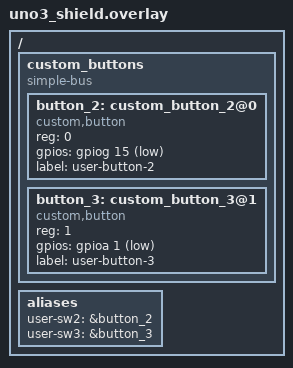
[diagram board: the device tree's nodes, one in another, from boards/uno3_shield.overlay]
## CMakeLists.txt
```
# SPDX-License-Identifier: Apache-2.0

cmake_minimum_required(VERSION 3.20.0)

set(ZEPHYR_EXTRA_MODULES
    "${CMAKE_SOURCE_DIR}/../modules/button"
    "${CMAKE_SOURCE_DIR}/../modules/say_hello"
)

find_package(Zephyr REQUIRED HINTS $ENV{ZEPHYR_BASE})
project(custom-button)

target_sources(app PRIVATE src/main.c)
```

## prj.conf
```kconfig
CONFIG_GPIO=y

# for random generator
CONFIG_STACK_POINTER_RANDOM=0
CONFIG_TEST_RANDOM_GENERATOR=y
CONFIG_TIMER_RANDOM_GENERATOR=y
CONFIG_TEST_CSPRNG_GENERATOR=y

# for float number print
# -LIBC_ERRNO y
# -PICOLIBC_IO_FLOAT n
# -PICOLIBC_IO_LONG_LONG y
# -PICOLIBC_USE_MODULE n
# -PICOLIBC_USE_TOOLCHAIN y
CONFIG_NEWLIB_LIBC=y
CONFIG_PICOLIBC=n
CONFIG_CBPRINTF_FP_ALWAYS_A=n
CONFIG_CBPRINTF_N_SPECIFIER=y
CONFIG_ERRNO_IN_TLS=y
CONFIG_NEWLIB_LIBC_CUSTOM_SBRK=n
CONFIG_NEWLIB_LIBC_FLOAT_PRINTF=n
CONFIG_NEWLIB_LIBC_FLOAT_SCANF=n
CONFIG_NEWLIB_LIBC_HEAP_LISTENER=n
CONFIG_NEWLIB_LIBC_MIN_REQUIRED_HEAP_SIZE=8192
CONFIG_NEWLIB_LIBC_NANO=n

# for say_hello modules
CONFIG_SAY_HELLO=y

# for custom button driver
CONFIG_CUSTOM_DRIVERS_BUTTON=y

# for logging module
CONFIG_LOG=y
CONFIG_LOG_DEFAULT_LEVEL=4
```

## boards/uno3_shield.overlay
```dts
/ {
    custom_buttons {
        /* This node is a simple container for our buttons */
        compatible = "simple-bus";
        #address-cells = <1>;
        #size-cells = <0>;

        button_2: custom_button_2@0 {
            compatible = "custom,button";
            reg = <0>;
            /* The 'gpios' property is now directly inside the node */
            gpios = <&gpiog 15 (GPIO_ACTIVE_LOW | GPIO_PULL_UP)>;
            label = "user-button-2";
        };

        button_3: custom_button_3@1 {
            compatible = "custom,button";
            reg = <1>;
            /* The 'gpios' property is now directly inside the node */
            gpios = <&gpioa 1 (GPIO_ACTIVE_LOW | GPIO_PULL_UP)>;
            label = "user-button-3";
        };
    };

    aliases {
        /* Aliases now point to the correct nodes */
        user-sw2 = &button_2;
        user-sw3 = &button_3;
    };
};
```

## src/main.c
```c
#include <zephyr/kernel.h>
#include <zephyr/sys/printk.h>
#include <zephyr/devicetree.h>
#include <zephyr/device.h>
#include <say_hello.h>
#include "button.h"

/*
 * Get the node identifiers for the user buttons that are actually defined.
 */
#define USER_BUTTON_NODE2 DT_ALIAS(user_sw2)
#define USER_BUTTON_NODE3 DT_ALIAS(user_sw3)

/*
 * A build-time check that the aliases exist in the devicetree.
 */
#if !DT_NODE_HAS_STATUS(USER_BUTTON_NODE2, okay)
#error "Unsupported board: user_sw2 devicetree alias is not defined"
#endif

#if !DT_NODE_HAS_STATUS(USER_BUTTON_NODE3, okay)
#error "Unsupported board: user_sw3 devicetree alias is not defined"
#endif

/*
 * Get the device pointers for the buttons.
 */
static const struct device *user_button2 = DEVICE_DT_GET(USER_BUTTON_NODE2);
static const struct device *user_button3 = DEVICE_DT_GET(USER_BUTTON_NODE3);

void main(void)
{
	printk("Hello World! %s\n", CONFIG_BOARD);
	say_hello();

	if (!device_is_ready(user_button2) || !device_is_ready(user_button3)) {
		printk("Error: One or more custom button devices are not ready\n");
		return;
	}

	printk("Custom button devices are ready. Polling...\n");

	while(1) {
		/* Get the API from the device struct for button 2 */
		const struct button_api *api2 = user_button2->api;
		if (api2 && api2->get_press_state) {
			if (api2->get_press_state(user_button2) > 0) {
				printk("Button 2 is pressed!\n");
			}
		}

		/* Get the API from the device struct for button 3 */
		const struct button_api *api3 = user_button3->api;
		if (api3 && api3->get_press_state) {
			if (api3->get_press_state(user_button3) > 0) {
				printk("Button 3 is pressed!\n");
			}
		}

		k_msleep(200);
	}
}
```
